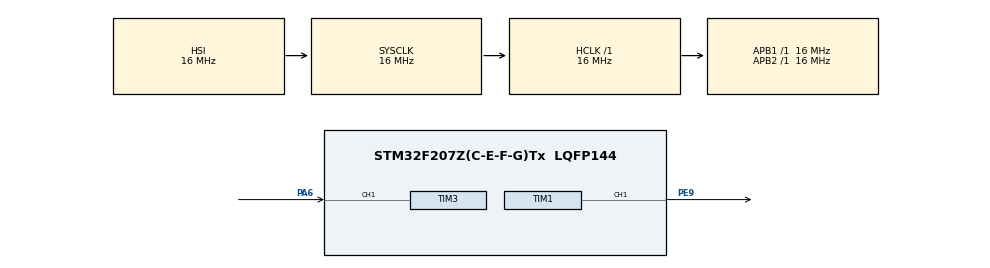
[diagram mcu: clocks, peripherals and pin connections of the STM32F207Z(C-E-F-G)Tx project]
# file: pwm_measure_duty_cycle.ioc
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Mcu.Family=STM32F2
Mcu.Name=STM32F207Z(C-E-F-G)Tx
Mcu.Package=LQFP144
NVIC.PriorityGroup=NVIC_PRIORITYGROUP_4
NVIC.TIM1_BRK_TIM9_IRQn=true\:0\:0\:false\:false\:true\:true\:true\:true
NVIC.TIM1_CC_IRQn=true\:0\:0\:false\:false\:true\:true\:true\:true
NVIC.TIM1_TRG_COM_TIM11_IRQn=true\:0\:0\:false\:false\:true\:true\:true\:true
NVIC.TIM1_UP_TIM10_IRQn=true\:0\:0\:false\:false\:true\:true\:true\:true
NVIC.TIM3_IRQn=true\:0\:0\:false\:false\:true\:true\:true\:true
PA6.Signal=S_TIM3_CH1
PE9.Signal=S_TIM1_CH1
ProjectManager.HeapSize=0x200
ProjectManager.StackSize=0x400
ProjectManager.TargetToolchain=STM32CubeIDE
RCC.48MHZClocksFreq_Value=48000000
RCC.AHBFreq_Value=16000000
RCC.APB1Freq_Value=16000000
RCC.APB2Freq_Value=16000000
RCC.CortexFreq_Value=16000000
RCC.HSE_VALUE=25000000
RCC.HSI_VALUE=16000000
RCC.LSE_VALUE=32768
RCC.SYSCLKFreq_VALUE=16000000
RCC.VCOOutputFreq_Value=192000000
SH.S_TIM1_CH1.0=TIM1_CH1,PWM Generation1 CH1
SH.S_TIM3_CH1.0=TIM3_CH1,PWM_Input_1
TIM1.Channel-PWM\ Generation1\ CH1=TIM_CHANNEL_1
TIM1.Period=10 - 1
TIM1.Prescaler=16000 - 1
TIM1.Pulse-PWM\ Generation1\ CH1=9
TIM3.Period=100 - 1
TIM3.Prescaler=1600 - 1
VP_TIM1_VS_ClockSourceINT.Mode=Internal
VP_TIM3_VS_ClockSourceINT.Mode=Internal
board=custom

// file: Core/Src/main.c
/* USER CODE BEGIN Header */
/**
  ******************************************************************************
  * @file           : main.c
  * @brief          : Main program body
  ******************************************************************************
  * @attention
  *
  * Copyright (c) 2023 STMicroelectronics.
  * All rights reserved.
  *
  * This software is licensed under terms that can be found in the LICENSE file
  * in the root directory of this software component.
  * If no LICENSE file comes with this software, it is provided AS-IS.
  *
  ******************************************************************************
  */
/* USER CODE END Header */
#include "main.h"

TIM_HandleTypeDef htim1;
TIM_HandleTypeDef htim3;

/* USER CODE BEGIN PV */
uint32_t risingEdgeTime = 0;
uint32_t fallingEdgeTime = 0;
uint32_t frequency;
float duty;
uint32_t pulseWidth;
/* USER CODE END PV */

void SystemClock_Config(void);
static void MX_GPIO_Init(void);
static void MX_TIM1_Init(void);
static void MX_TIM3_Init(void);

/* USER CODE BEGIN 0 */
void HAL_TIM_IC_CaptureCallback(TIM_HandleTypeDef *htim)
{
	if (htim->Instance == TIM3) {
			risingEdgeTime = HAL_TIM_ReadCapturedValue(htim, TIM_CHANNEL_1);
			fallingEdgeTime = HAL_TIM_ReadCapturedValue(htim, TIM_CHANNEL_2);

			frequency = (float) risingEdgeTime + 1;
			duty = (float) 100 * fallingEdgeTime / risingEdgeTime;
		}
}
/* USER CODE END 0 */

int main(void)
{

  /* MCU Configuration--------------------------------------------------------*/

  /* Reset of all peripherals, Initializes the Flash interface and the Systick. */
  HAL_Init();

  /* Configure the system clock */
  SystemClock_Config();

  /* Initialize all configured peripherals */
  MX_GPIO_Init();
  MX_TIM1_Init();
  MX_TIM3_Init();
  /* USER CODE BEGIN 2 */
  /*if (__HAL_TIM_GET_FLAG(&htim3, TIM_FLAG_UPDATE) != RESET)
 	  __HAL_TIM_CLEAR_FLAG(&htim3, TIM_FLAG_UPDATE);
   if (__HAL_TIM_GET_FLAG(&htim1, TIM_FLAG_UPDATE) != RESET)
  	  __HAL_TIM_CLEAR_FLAG(&htim1, TIM_FLAG_UPDATE);*/
  TIM1->CCR1 = 11;
  HAL_TIM_PWM_Start(&htim1, TIM_CHANNEL_1);
   HAL_TIM_IC_Start_IT(&htim3, TIM_CHANNEL_1);
   HAL_TIM_IC_Start(&htim3, TIM_CHANNEL_2);
  // HAL_TIM_Base_Start_IT(&htim3);
  /* USER CODE END 2 */

  /* Infinite loop */
  while (1)
  {

  }
}

void SystemClock_Config(void)
{
  RCC_OscInitTypeDef RCC_OscInitStruct = {0};
  RCC_ClkInitTypeDef RCC_ClkInitStruct = {0};

  /** Initializes the RCC Oscillators according to the specified parameters
  * in the RCC_OscInitTypeDef structure.
  */
  RCC_OscInitStruct.OscillatorType = RCC_OSCILLATORTYPE_HSI;
  RCC_OscInitStruct.HSIState = RCC_HSI_ON;
  RCC_OscInitStruct.HSICalibrationValue = RCC_HSICALIBRATION_DEFAULT;
  RCC_OscInitStruct.PLL.PLLState = RCC_PLL_NONE;
  if (HAL_RCC_OscConfig(&RCC_OscInitStruct) != HAL_OK)
  {
    Error_Handler();
  }

  /** Initializes the CPU, AHB and APB buses clocks
  */
  RCC_ClkInitStruct.ClockType = RCC_CLOCKTYPE_HCLK|RCC_CLOCKTYPE_SYSCLK
                              |RCC_CLOCKTYPE_PCLK1|RCC_CLOCKTYPE_PCLK2;
  RCC_ClkInitStruct.SYSCLKSource = RCC_SYSCLKSOURCE_HSI;
  RCC_ClkInitStruct.AHBCLKDivider = RCC_SYSCLK_DIV1;
  RCC_ClkInitStruct.APB1CLKDivider = RCC_HCLK_DIV1;
  RCC_ClkInitStruct.APB2CLKDivider = RCC_HCLK_DIV1;

  if (HAL_RCC_ClockConfig(&RCC_ClkInitStruct, FLASH_LATENCY_0) != HAL_OK)
  {
    Error_Handler();
  }
}

static void MX_TIM1_Init(void)
{

  TIM_ClockConfigTypeDef sClockSourceConfig = {0};
  TIM_MasterConfigTypeDef sMasterConfig = {0};
  TIM_OC_InitTypeDef sConfigOC = {0};
  TIM_BreakDeadTimeConfigTypeDef sBreakDeadTimeConfig = {0};

  htim1.Instance = TIM1;
  htim1.Init.Prescaler = 16000 - 1;
  htim1.Init.CounterMode = TIM_COUNTERMODE_UP;
  htim1.Init.Period = 10 - 1;
  htim1.Init.ClockDivision = TIM_CLOCKDIVISION_DIV1;
  htim1.Init.RepetitionCounter = 0;
  htim1.Init.AutoReloadPreload = TIM_AUTORELOAD_PRELOAD_DISABLE;
  if (HAL_TIM_Base_Init(&htim1) != HAL_OK)
  {
    Error_Handler();
  }
  sClockSourceConfig.ClockSource = TIM_CLOCKSOURCE_INTERNAL;
  if (HAL_TIM_ConfigClockSource(&htim1, &sClockSourceConfig) != HAL_OK)
  {
    Error_Handler();
  }
  if (HAL_TIM_PWM_Init(&htim1) != HAL_OK)
  {
    Error_Handler();
  }
  sMasterConfig.MasterOutputTrigger = TIM_TRGO_RESET;
  sMasterConfig.MasterSlaveMode = TIM_MASTERSLAVEMODE_DISABLE;
  if (HAL_TIMEx_MasterConfigSynchronization(&htim1, &sMasterConfig) != HAL_OK)
  {
    Error_Handler();
  }
  sConfigOC.OCMode = TIM_OCMODE_PWM1;
  sConfigOC.Pulse = 9;
  sConfigOC.OCPolarity = TIM_OCPOLARITY_HIGH;
  sConfigOC.OCNPolarity = TIM_OCNPOLARITY_HIGH;
  sConfigOC.OCFastMode = TIM_OCFAST_DISABLE;
  sConfigOC.OCIdleState = TIM_OCIDLESTATE_RESET;
  sConfigOC.OCNIdleState = TIM_OCNIDLESTATE_RESET;
  if (HAL_TIM_PWM_ConfigChannel(&htim1, &sConfigOC, TIM_CHANNEL_1) != HAL_OK)
  {
    Error_Handler();
  }
  sBreakDeadTimeConfig.OffStateRunMode = TIM_OSSR_DISABLE;
  sBreakDeadTimeConfig.OffStateIDLEMode = TIM_OSSI_DISABLE;
  sBreakDeadTimeConfig.LockLevel = TIM_LOCKLEVEL_OFF;
  sBreakDeadTimeConfig.DeadTime = 0;
  sBreakDeadTimeConfig.BreakState = TIM_BREAK_DISABLE;
  sBreakDeadTimeConfig.BreakPolarity = TIM_BREAKPOLARITY_HIGH;
  sBreakDeadTimeConfig.AutomaticOutput = TIM_AUTOMATICOUTPUT_DISABLE;
  if (HAL_TIMEx_ConfigBreakDeadTime(&htim1, &sBreakDeadTimeConfig) != HAL_OK)
  {
    Error_Handler();
  }
  HAL_TIM_MspPostInit(&htim1);

}

static void MX_TIM3_Init(void)
{

  TIM_ClockConfigTypeDef sClockSourceConfig = {0};
  TIM_SlaveConfigTypeDef sSlaveConfig = {0};
  TIM_IC_InitTypeDef sConfigIC = {0};
  TIM_MasterConfigTypeDef sMasterConfig = {0};

  htim3.Instance = TIM3;
  htim3.Init.Prescaler = 1600 - 1;
  htim3.Init.CounterMode = TIM_COUNTERMODE_UP;
  htim3.Init.Period = 100 - 1;
  htim3.Init.ClockDivision = TIM_CLOCKDIVISION_DIV1;
  htim3.Init.AutoReloadPreload = TIM_AUTORELOAD_PRELOAD_DISABLE;
  if (HAL_TIM_Base_Init(&htim3) != HAL_OK)
  {
    Error_Handler();
  }
  sClockSourceConfig.ClockSource = TIM_CLOCKSOURCE_INTERNAL;
  if (HAL_TIM_ConfigClockSource(&htim3, &sClockSourceConfig) != HAL_OK)
  {
    Error_Handler();
  }
  if (HAL_TIM_IC_Init(&htim3) != HAL_OK)
  {
    Error_Handler();
  }
  sSlaveConfig.SlaveMode = TIM_SLAVEMODE_RESET;
  sSlaveConfig.InputTrigger = TIM_TS_TI1FP1;
  sSlaveConfig.TriggerPolarity = TIM_INPUTCHANNELPOLARITY_RISING;
  sSlaveConfig.TriggerPrescaler = TIM_ICPSC_DIV1;
  sSlaveConfig.TriggerFilter = 0;
  if (HAL_TIM_SlaveConfigSynchro(&htim3, &sSlaveConfig) != HAL_OK)
  {
    Error_Handler();
  }
  sConfigIC.ICPolarity = TIM_INPUTCHANNELPOLARITY_RISING;
  sConfigIC.ICSelection = TIM_ICSELECTION_DIRECTTI;
  sConfigIC.ICPrescaler = TIM_ICPSC_DIV1;
  sConfigIC.ICFilter = 0;
  if (HAL_TIM_IC_ConfigChannel(&htim3, &sConfigIC, TIM_CHANNEL_1) != HAL_OK)
  {
    Error_Handler();
  }
  sConfigIC.ICPolarity = TIM_INPUTCHANNELPOLARITY_FALLING;
  sConfigIC.ICSelection = TIM_ICSELECTION_INDIRECTTI;
  if (HAL_TIM_IC_ConfigChannel(&htim3, &sConfigIC, TIM_CHANNEL_2) != HAL_OK)
  {
    Error_Handler();
  }
  sMasterConfig.MasterOutputTrigger = TIM_TRGO_RESET;
  sMasterConfig.MasterSlaveMode = TIM_MASTERSLAVEMODE_DISABLE;
  if (HAL_TIMEx_MasterConfigSynchronization(&htim3, &sMasterConfig) != HAL_OK)
  {
    Error_Handler();
  }

}

static void MX_GPIO_Init(void)
{

  /* GPIO Ports Clock Enable */
  __HAL_RCC_GPIOA_CLK_ENABLE();
  __HAL_RCC_GPIOE_CLK_ENABLE();

}

void Error_Handler(void)
{
  __disable_irq();
  while (1)
  {
  }
}
